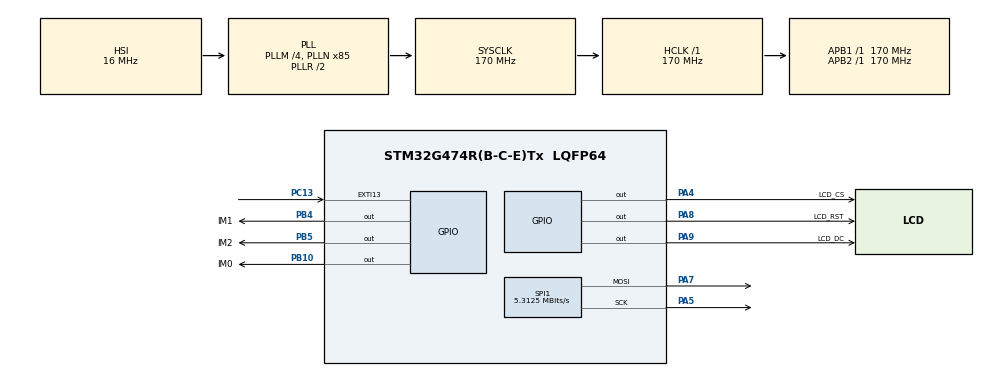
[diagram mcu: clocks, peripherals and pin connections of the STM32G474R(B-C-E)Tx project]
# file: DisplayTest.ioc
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Dma.Request0=SPI1_TX
Dma.SPI1_TX.0.Direction=DMA_MEMORY_TO_PERIPH
Dma.SPI1_TX.0.EventEnable=DISABLE
Dma.SPI1_TX.0.Instance=DMA1_Channel1
Dma.SPI1_TX.0.MemDataAlignment=DMA_MDATAALIGN_BYTE
Dma.SPI1_TX.0.MemInc=DMA_MINC_ENABLE
Dma.SPI1_TX.0.Mode=DMA_NORMAL
Dma.SPI1_TX.0.PeriphDataAlignment=DMA_PDATAALIGN_BYTE
Dma.SPI1_TX.0.PeriphInc=DMA_PINC_DISABLE
Dma.SPI1_TX.0.Polarity=HAL_DMAMUX_REQ_GEN_RISING
Dma.SPI1_TX.0.Priority=DMA_PRIORITY_LOW
Dma.SPI1_TX.0.RequestNumber=1
Dma.SPI1_TX.0.SignalID=NONE
Dma.SPI1_TX.0.SyncEnable=DISABLE
Dma.SPI1_TX.0.SyncPolarity=HAL_DMAMUX_SYNC_NO_EVENT
Dma.SPI1_TX.0.SyncRequestNumber=1
Dma.SPI1_TX.0.SyncSignalID=NONE
Mcu.Family=STM32G4
Mcu.Name=STM32G474R(B-C-E)Tx
Mcu.Package=LQFP64
NUCLEO-G474RE.BUTTON=1
NUCLEO-G474RE.LD2=false
NUCLEO-G474RE.VCP=true
NVIC.DMA1_Channel1_IRQn=true\:0\:0\:false\:false\:true\:false\:true\:true
NVIC.EXTI15_10_IRQn=true\:0\:0\:false\:false\:true\:true\:true\:true
NVIC.PriorityGroup=NVIC_PRIORITYGROUP_4
PA13.GPIO_Label=T_SWDIO
PA13.Signal=SYS_JTMS-SWDIO
PA14.GPIO_Label=T_SWCLK
PA14.Signal=SYS_JTCK-SWCLK
PA2.Signal=LPUART1_TX
PA3.Signal=LPUART1_RX
PA4.GPIO_Label=LCD_CS
PA4.Signal=GPIO_Output
PA5.Mode=TX_Only_Simplex_Unidirect_Master
PA5.Signal=SPI1_SCK
PA7.Mode=TX_Only_Simplex_Unidirect_Master
PA7.Signal=SPI1_MOSI
PA8.GPIO_Label=LCD_RST
PA8.Signal=GPIO_Output
PA9.GPIO_Label=LCD_DC
PA9.Signal=GPIO_Output
PB10.GPIO_Label=IM0
PB10.Signal=GPIO_Output
PB3.GPIO_Label=T_SWO
PB3.Signal=SYS_JTDO-SWO
PB4.GPIO_Label=IM1
PB4.Signal=GPIO_Output
PB5.GPIO_Label=IM2
PB5.Signal=GPIO_Output
PC13.Signal=GPXTI13
PC14-OSC32_IN.GPIO_Label=RCC_OSC32_IN
PC14-OSC32_IN.Signal=RCC_OSC32_IN
PC15-OSC32_OUT.GPIO_Label=RCC_OSC32_OUT
PC15-OSC32_OUT.Signal=RCC_OSC32_OUT
PF0-OSC_IN.GPIO_Label=RCC_OSC_IN
PF0-OSC_IN.Signal=RCC_OSC_IN
PF1-OSC_OUT.GPIO_Label=RCC_OSC_OUT
PF1-OSC_OUT.Signal=RCC_OSC_OUT
ProjectManager.HeapSize=0x200
ProjectManager.StackSize=0x400
ProjectManager.TargetToolchain=STM32CubeIDE
RCC.ADC12Freq_Value=170000000
RCC.ADC345Freq_Value=170000000
RCC.AHBFreq_Value=170000000
RCC.APB1Freq_Value=170000000
RCC.APB1TimFreq_Value=170000000
RCC.APB2Freq_Value=170000000
RCC.APB2TimFreq_Value=170000000
RCC.CortexFreq_Value=170000000
RCC.EXTERNAL_CLOCK_VALUE=12288000
RCC.HCLKFreq_Value=170000000
RCC.HSE_VALUE=24000000
RCC.HSI48_VALUE=48000000
RCC.HSI_VALUE=16000000
RCC.LSE_VALUE=32768
RCC.PLLM=RCC_PLLM_DIV4
RCC.PLLN=85
RCC.RTCClockSelection=RCC_RTCCLKSOURCE_LSE
RCC.SYSCLKFreq_VALUE=170000000
RCC.SYSCLKSource=RCC_SYSCLKSOURCE_PLLCLK
RCC.USBFreq_Value=170000000
RCC.VCOOutputFreq_Value=340000000
SPI1.BaudRatePrescaler=SPI_BAUDRATEPRESCALER_32
SPI1.CLKPolarity=SPI_POLARITY_LOW
SPI1.CalculateBaudRate=5.3125 MBits/s
SPI1.DataSize=SPI_DATASIZE_9BIT
SPI1.Direction=SPI_DIRECTION_2LINES
SPI1.Mode=SPI_MODE_MASTER
SPI1.VirtualType=VM_MASTER
VP_NUCLEO-G474RE_VS_BSP_COMMON.Mode=COMMON
VP_SYS_VS_DBSignals.Mode=DisableDeadBatterySignals
board=NUCLEO-G474RE

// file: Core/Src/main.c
/* USER CODE BEGIN Header */
/**
  ******************************************************************************
  * @file           : main.c
  * @brief          : Main program body
  ******************************************************************************
  * @attention
  *
  * Copyright (c) 2025 STMicroelectronics.
  * All rights reserved.
  *
  * This software is licensed under terms that can be found in the LICENSE file
  * in the root directory of this software component.
  * If no LICENSE file comes with this software, it is provided AS-IS.
  *
  ******************************************************************************
  */
/* USER CODE END Header */
#include "main.h"

COM_InitTypeDef BspCOMInit;
SPI_HandleTypeDef hspi1;
DMA_HandleTypeDef hdma_spi1_tx;

void SystemClock_Config(void);
static void MX_GPIO_Init(void);
static void MX_DMA_Init(void);
static void MX_SPI1_Init(void);

int main(void)
{

  /* MCU Configuration--------------------------------------------------------*/

  /* Reset of all peripherals, Initializes the Flash interface and the Systick. */
  HAL_Init();

  /* Configure the system clock */
  SystemClock_Config();

  /* Initialize all configured peripherals */
  MX_GPIO_Init();
  MX_DMA_Init();
  MX_SPI1_Init();
  /* USER CODE BEGIN 2 */
  HAL_GPIO_WritePin(IM0_GPIO_Port, IM0_Pin, 1);
  HAL_GPIO_WritePin(IM1_GPIO_Port, IM1_Pin, 1);
  HAL_GPIO_WritePin(IM2_GPIO_Port, IM2_Pin, 0);
  LCD_init();
  /* USER CODE END 2 */

  /* Initialize USER push-button, will be used to trigger an interrupt each time it's pressed.*/
  BSP_PB_Init(BUTTON_USER, BUTTON_MODE_EXTI);

  /* Initialize COM1 port (115200, 8 bits (7-bit data + 1 stop bit), no parity */
  BspCOMInit.BaudRate   = 115200;
  BspCOMInit.WordLength = COM_WORDLENGTH_8B;
  BspCOMInit.StopBits   = COM_STOPBITS_1;
  BspCOMInit.Parity     = COM_PARITY_NONE;
  BspCOMInit.HwFlowCtl  = COM_HWCONTROL_NONE;
  if (BSP_COM_Init(COM1, &BspCOMInit) != BSP_ERROR_NONE)
  {
    Error_Handler();
  }

  /* Infinite loop */
  /* USER CODE BEGIN WHILE */
  while (1)
  {
	  LCD_Test();
    /* USER CODE END WHILE */

  }
}

void SystemClock_Config(void)
{
  RCC_OscInitTypeDef RCC_OscInitStruct = {0};
  RCC_ClkInitTypeDef RCC_ClkInitStruct = {0};

  /** Configure the main internal regulator output voltage
  */
  HAL_PWREx_ControlVoltageScaling(PWR_REGULATOR_VOLTAGE_SCALE1_BOOST);

  /** Initializes the RCC Oscillators according to the specified parameters
  * in the RCC_OscInitTypeDef structure.
  */
  RCC_OscInitStruct.OscillatorType = RCC_OSCILLATORTYPE_HSI;
  RCC_OscInitStruct.HSIState = RCC_HSI_ON;
  RCC_OscInitStruct.HSICalibrationValue = RCC_HSICALIBRATION_DEFAULT;
  RCC_OscInitStruct.PLL.PLLState = RCC_PLL_ON;
  RCC_OscInitStruct.PLL.PLLSource = RCC_PLLSOURCE_HSI;
  RCC_OscInitStruct.PLL.PLLM = RCC_PLLM_DIV4;
  RCC_OscInitStruct.PLL.PLLN = 85;
  RCC_OscInitStruct.PLL.PLLP = RCC_PLLP_DIV2;
  RCC_OscInitStruct.PLL.PLLQ = RCC_PLLQ_DIV2;
  RCC_OscInitStruct.PLL.PLLR = RCC_PLLR_DIV2;
  if (HAL_RCC_OscConfig(&RCC_OscInitStruct) != HAL_OK)
  {
    Error_Handler();
  }

  /** Initializes the CPU, AHB and APB buses clocks
  */
  RCC_ClkInitStruct.ClockType = RCC_CLOCKTYPE_HCLK|RCC_CLOCKTYPE_SYSCLK
                              |RCC_CLOCKTYPE_PCLK1|RCC_CLOCKTYPE_PCLK2;
  RCC_ClkInitStruct.SYSCLKSource = RCC_SYSCLKSOURCE_PLLCLK;
  RCC_ClkInitStruct.AHBCLKDivider = RCC_SYSCLK_DIV1;
  RCC_ClkInitStruct.APB1CLKDivider = RCC_HCLK_DIV1;
  RCC_ClkInitStruct.APB2CLKDivider = RCC_HCLK_DIV1;

  if (HAL_RCC_ClockConfig(&RCC_ClkInitStruct, FLASH_LATENCY_4) != HAL_OK)
  {
    Error_Handler();
  }
}

static void MX_SPI1_Init(void)
{

  /* SPI1 parameter configuration*/
  hspi1.Instance = SPI1;
  hspi1.Init.Mode = SPI_MODE_MASTER;
  hspi1.Init.Direction = SPI_DIRECTION_2LINES;
  hspi1.Init.DataSize = SPI_DATASIZE_9BIT;
  hspi1.Init.CLKPolarity = SPI_POLARITY_LOW;
  hspi1.Init.CLKPhase = SPI_PHASE_1EDGE;
  hspi1.Init.NSS = SPI_NSS_SOFT;
  hspi1.Init.BaudRatePrescaler = SPI_BAUDRATEPRESCALER_32;
  hspi1.Init.FirstBit = SPI_FIRSTBIT_MSB;
  hspi1.Init.TIMode = SPI_TIMODE_DISABLE;
  hspi1.Init.CRCCalculation = SPI_CRCCALCULATION_DISABLE;
  hspi1.Init.CRCPolynomial = 7;
  hspi1.Init.CRCLength = SPI_CRC_LENGTH_DATASIZE;
  hspi1.Init.NSSPMode = SPI_NSS_PULSE_ENABLE;
  if (HAL_SPI_Init(&hspi1) != HAL_OK)
  {
    Error_Handler();
  }

}

static void MX_DMA_Init(void)
{

  /* DMA controller clock enable */
  __HAL_RCC_DMAMUX1_CLK_ENABLE();
  __HAL_RCC_DMA1_CLK_ENABLE();

  /* DMA interrupt init */
  /* DMA1_Channel1_IRQn interrupt configuration */
  HAL_NVIC_SetPriority(DMA1_Channel1_IRQn, 0, 0);
  HAL_NVIC_EnableIRQ(DMA1_Channel1_IRQn);

}

static void MX_GPIO_Init(void)
{
  GPIO_InitTypeDef GPIO_InitStruct = {0};

  /* GPIO Ports Clock Enable */
  __HAL_RCC_GPIOC_CLK_ENABLE();
  __HAL_RCC_GPIOF_CLK_ENABLE();
  __HAL_RCC_GPIOA_CLK_ENABLE();
  __HAL_RCC_GPIOB_CLK_ENABLE();

  /*Configure GPIO pin Output Level */
  HAL_GPIO_WritePin(GPIOA, LCD_CS_Pin|LCD_RST_Pin|LCD_DC_Pin, GPIO_PIN_RESET);

  /*Configure GPIO pin Output Level */
  HAL_GPIO_WritePin(GPIOB, IM0_Pin|IM1_Pin|IM2_Pin, GPIO_PIN_RESET);

  /*Configure GPIO pins : LCD_CS_Pin LCD_RST_Pin LCD_DC_Pin */
  GPIO_InitStruct.Pin = LCD_CS_Pin|LCD_RST_Pin|LCD_DC_Pin;
  GPIO_InitStruct.Mode = GPIO_MODE_OUTPUT_PP;
  GPIO_InitStruct.Pull = GPIO_NOPULL;
  GPIO_InitStruct.Speed = GPIO_SPEED_FREQ_LOW;
  HAL_GPIO_Init(GPIOA, &GPIO_InitStruct);

  /*Configure GPIO pins : IM0_Pin IM1_Pin IM2_Pin */
  GPIO_InitStruct.Pin = IM0_Pin|IM1_Pin|IM2_Pin;
  GPIO_InitStruct.Mode = GPIO_MODE_OUTPUT_PP;
  GPIO_InitStruct.Pull = GPIO_NOPULL;
  GPIO_InitStruct.Speed = GPIO_SPEED_FREQ_LOW;
  HAL_GPIO_Init(GPIOB, &GPIO_InitStruct);

}

void Error_Handler(void)
{
  __disable_irq();
  while (1)
  {
  }
}
